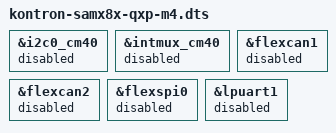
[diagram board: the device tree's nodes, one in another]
/dts-v1/;

#include "kontron-samx8x-qxp.dts"

&i2c0_cm40 {
    status = "disabled";
};

&intmux_cm40 {
    status = "disabled";
};

&flexcan1 {
    status = "disabled";
};

&flexcan2 {
    status = "disabled";
};

&flexspi0 {
    status = "disabled";
};

&lpuart1 {
    status = "disabled";
};
